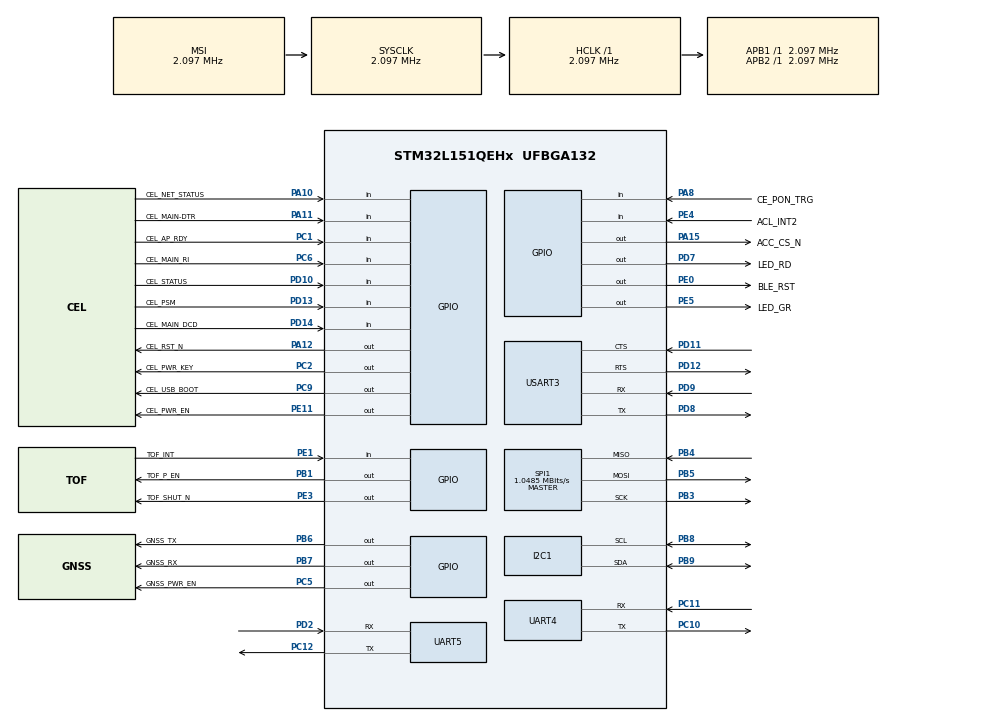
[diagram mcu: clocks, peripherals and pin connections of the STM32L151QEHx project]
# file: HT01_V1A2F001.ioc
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Dma.Request0=USART3_RX
Dma.USART3_RX.0.Direction=DMA_PERIPH_TO_MEMORY
Dma.USART3_RX.0.Instance=DMA1_Channel3
Dma.USART3_RX.0.MemDataAlignment=DMA_MDATAALIGN_BYTE
Dma.USART3_RX.0.MemInc=DMA_MINC_ENABLE
Dma.USART3_RX.0.Mode=DMA_NORMAL
Dma.USART3_RX.0.PeriphDataAlignment=DMA_PDATAALIGN_BYTE
Dma.USART3_RX.0.PeriphInc=DMA_PINC_DISABLE
Dma.USART3_RX.0.Priority=DMA_PRIORITY_LOW
Mcu.Family=STM32L1
Mcu.Name=STM32L151QEHx
Mcu.Package=UFBGA132
NVIC.DMA1_Channel3_IRQn=true\:0\:0\:false\:false\:true\:false\:true\:true
NVIC.PriorityGroup=NVIC_PRIORITYGROUP_4
NVIC.RTC_WKUP_IRQn=true\:0\:0\:false\:false\:true\:true\:true\:true
NVIC.USART3_IRQn=true\:0\:0\:false\:false\:true\:true\:true\:true
PA10.GPIO_Label=CEL_NET_STATUS
PA10.Signal=GPIO_Input
PA11.GPIO_Label=CEL_MAIN-DTR
PA11.Signal=GPIO_Input
PA12.GPIO_Label=CEL_RST_N
PA12.GPIO_PuPd=GPIO_PULLUP
PA12.Signal=GPIO_Output
PA13.Mode=Serial_Wire
PA13.Signal=SYS_JTMS-SWDIO
PA14.Mode=Serial_Wire
PA14.Signal=SYS_JTCK-SWCLK
PA15.GPIO_Label=ACC_CS_N
PA15.Signal=GPIO_Output
PA8.GPIO_Label=CE_PON_TRG
PA8.Signal=GPIO_Input
PB1.GPIO_Label=TOF_P_EN
PB1.GPIO_PuPd=GPIO_PULLUP
PB1.Signal=GPIO_Output
PB3.Mode=Full_Duplex_Master
PB3.Signal=SPI1_SCK
PB4.Mode=Full_Duplex_Master
PB4.Signal=SPI1_MISO
PB5.Mode=Full_Duplex_Master
PB5.Signal=SPI1_MOSI
PB6.GPIO_Label=GNSS_TX
PB6.Signal=GPIO_Output
PB7.GPIO_Label=GNSS_RX
PB7.Signal=GPIO_Output
PB8.Mode=I2C
PB8.Signal=I2C1_SCL
PB9.Mode=I2C
PB9.Signal=I2C1_SDA
PC1.GPIO_Label=CEL_AP_RDY
PC1.Signal=GPIO_Input
PC10.Mode=Asynchronous
PC10.Signal=UART4_TX
PC11.Mode=Asynchronous
PC11.Signal=UART4_RX
PC12.Mode=Asynchronous
PC12.Signal=UART5_TX
PC14-OSC32_IN.Mode=LSE-External-Oscillator
PC14-OSC32_IN.Signal=RCC_OSC32_IN
PC15-OSC32_OUT.Mode=LSE-External-Oscillator
PC15-OSC32_OUT.Signal=RCC_OSC32_OUT
PC2.GPIO_Label=CEL_PWR_KEY
PC2.Signal=GPIO_Output
PC5.GPIO_Label=GNSS_PWR_EN
PC5.Signal=GPIO_Output
PC6.GPIO_Label=CEL_MAIN_RI
PC6.Signal=GPIO_Input
PC9.GPIO_Label=CEL_USB_BOOT
PC9.Signal=GPIO_Output
PD10.GPIO_Label=CEL_STATUS
PD10.Signal=GPIO_Input
PD11.Mode=CTS_RTS
PD11.Signal=USART3_CTS
PD12.Mode=CTS_RTS
PD12.Signal=USART3_RTS
PD13.GPIO_Label=CEL_PSM
PD13.Signal=GPIO_Input
PD14.GPIO_Label=CEL_MAIN_DCD
PD14.Signal=GPIO_Input
PD2.Mode=Asynchronous
PD2.Signal=UART5_RX
PD7.GPIO_Label=LED_RD
PD7.Signal=GPIO_Output
PD8.Mode=Asynchronous
PD8.Signal=USART3_TX
PD9.Mode=Asynchronous
PD9.Signal=USART3_RX
PE0.GPIO_Label=BLE_RST
PE0.Signal=GPIO_Output
PE1.GPIO_Label=TOF_INT
PE1.Signal=GPIO_Input
PE11.GPIO_Label=CEL_PWR_EN
PE11.Signal=GPIO_Output
PE3.GPIO_Label=TOF_SHUT_N
PE3.GPIO_PuPd=GPIO_PULLUP
PE3.Signal=GPIO_Output
PE4.GPIO_Label=ACL_INT2
PE4.GPIO_PuPd=GPIO_PULLUP
PE4.Signal=GPIO_Input
PE5.GPIO_Label=LED_GR
PE5.Signal=GPIO_Output
PE6-WKUP3.Mode=SYS_WakeUp2
PE6-WKUP3.Signal=SYS_WKUP3
PH0-OSC_IN.Mode=HSE-External-Oscillator
PH0-OSC_IN.Signal=RCC_OSC_IN
PH1-OSC_OUT.Mode=HSE-External-Oscillator
PH1-OSC_OUT.Signal=RCC_OSC_OUT
ProjectManager.HeapSize=0x200
ProjectManager.StackSize=0x400
ProjectManager.TargetToolchain=STM32CubeIDE
RCC.AHBFreq_Value=2097000
RCC.APB1Freq_Value=2097000
RCC.APB2Freq_Value=2097000
RCC.HSE_VALUE=24000000
RCC.HSI_VALUE=16000000
RCC.MSI_VALUE=2097000
RCC.RTCClockSelection=RCC_RTCCLKSOURCE_LSE
RCC.SYSCLKFreq_VALUE=2097000
RCC.VCOOutputFreq_Value=48000000
RTC.WakeUpCounter-WakeUp=0xFFFF
SPI1.CalculateBaudRate=1.0485 MBits/s
SPI1.Direction=SPI_DIRECTION_2LINES
SPI1.Mode=SPI_MODE_MASTER
SPI1.VirtualType=VM_MASTER
UART4.VirtualMode=Asynchronous
UART5.VirtualMode=Asynchronous
USART3.VirtualMode=VM_ASYNC
VP_RTC_VS_RTC_Activate.Mode=RTC_Enabled
VP_RTC_VS_RTC_WakeUp_intern.Mode=WakeUp
board=custom

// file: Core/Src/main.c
/* USER CODE BEGIN Header */
/**
  ******************************************************************************
  * @file           : main.c
  * @brief          : Main program body
  ******************************************************************************
  * @attention
  *
  * Copyright (c) 2022 STMicroelectronics.
  * All rights reserved.
  *
  * This software is licensed under terms that can be found in the LICENSE file
  * in the root directory of this software component.
  * If no LICENSE file comes with this software, it is provided AS-IS.
  *
  ******************************************************************************
  */
/* USER CODE END Header */
#include "main.h"
#include "dma.h"
#include "i2c.h"
#include "rtc.h"
#include "spi.h"
#include "usart.h"
#include "gpio.h"

/* USER CODE BEGIN Includes */
#include "HT_main.h"

/* USER CODE END Includes */

void SystemClock_Config(void);

/* USER CODE BEGIN 0 */

uint8_t RxBuf[RxBuf_SIZE];

void HAL_UARTEx_RxEventCallback(UART_HandleTypeDef *huart, uint16_t size)
{
	if (huart->Instance == USART3) {
		HT_LOG(LOG_DEBUG, "%s", RxBuf);
		memset(RxBuf,'\0', RxBuf_SIZE);
	}
	HAL_UARTEx_ReceiveToIdle_DMA(&UART_DATA_IN_HANDLER, RxBuf, RxBuf_SIZE);
	__HAL_DMA_DISABLE_IT(&UART_DATA_IN_DMA, DMA_IT_HT);
}

/* USER CODE END 0 */

int main(void)
{

  /* MCU Configuration--------------------------------------------------------*/

  /* Reset of all peripherals, Initializes the Flash interface and the Systick. */
  HAL_Init();

  /* Configure the system clock */
  SystemClock_Config();

  /* Initialize all configured peripherals */
  MX_GPIO_Init();
  MX_DMA_Init();
  MX_I2C1_Init();
  MX_SPI1_Init();
  MX_UART4_Init();
  MX_UART5_Init();
  MX_USART3_UART_Init();
  MX_RTC_Init();
  /* USER CODE BEGIN 2 */

  HT_setup(NULL);

  /* USER CODE END 2 */

  /* Infinite loop */
  while (1)
  {

    /* USER CODE BEGIN 3 */
	  HT_loop(NULL);
  }
  /* USER CODE END 3 */
}

void SystemClock_Config(void)
{
  RCC_OscInitTypeDef RCC_OscInitStruct = {0};
  RCC_ClkInitTypeDef RCC_ClkInitStruct = {0};
  RCC_PeriphCLKInitTypeDef PeriphClkInit = {0};

  /** Configure the main internal regulator output voltage
  */
  __HAL_PWR_VOLTAGESCALING_CONFIG(PWR_REGULATOR_VOLTAGE_SCALE1);

  /** Initializes the RCC Oscillators according to the specified parameters
  * in the RCC_OscInitTypeDef structure.
  */
  RCC_OscInitStruct.OscillatorType = RCC_OSCILLATORTYPE_LSE|RCC_OSCILLATORTYPE_MSI;
  RCC_OscInitStruct.LSEState = RCC_LSE_ON;
  RCC_OscInitStruct.MSIState = RCC_MSI_ON;
  RCC_OscInitStruct.MSICalibrationValue = 0;
  RCC_OscInitStruct.MSIClockRange = RCC_MSIRANGE_5;
  RCC_OscInitStruct.PLL.PLLState = RCC_PLL_NONE;
  if (HAL_RCC_OscConfig(&RCC_OscInitStruct) != HAL_OK)
  {
    Error_Handler();
  }

  /** Initializes the CPU, AHB and APB buses clocks
  */
  RCC_ClkInitStruct.ClockType = RCC_CLOCKTYPE_HCLK|RCC_CLOCKTYPE_SYSCLK
                              |RCC_CLOCKTYPE_PCLK1|RCC_CLOCKTYPE_PCLK2;
  RCC_ClkInitStruct.SYSCLKSource = RCC_SYSCLKSOURCE_MSI;
  RCC_ClkInitStruct.AHBCLKDivider = RCC_SYSCLK_DIV1;
  RCC_ClkInitStruct.APB1CLKDivider = RCC_HCLK_DIV1;
  RCC_ClkInitStruct.APB2CLKDivider = RCC_HCLK_DIV1;

  if (HAL_RCC_ClockConfig(&RCC_ClkInitStruct, FLASH_LATENCY_0) != HAL_OK)
  {
    Error_Handler();
  }
  PeriphClkInit.PeriphClockSelection = RCC_PERIPHCLK_RTC;
  PeriphClkInit.RTCClockSelection = RCC_RTCCLKSOURCE_LSE;
  if (HAL_RCCEx_PeriphCLKConfig(&PeriphClkInit) != HAL_OK)
  {
    Error_Handler();
  }
}

void Error_Handler(void)
{
  __disable_irq();
  while (1)
  {
  }
}
